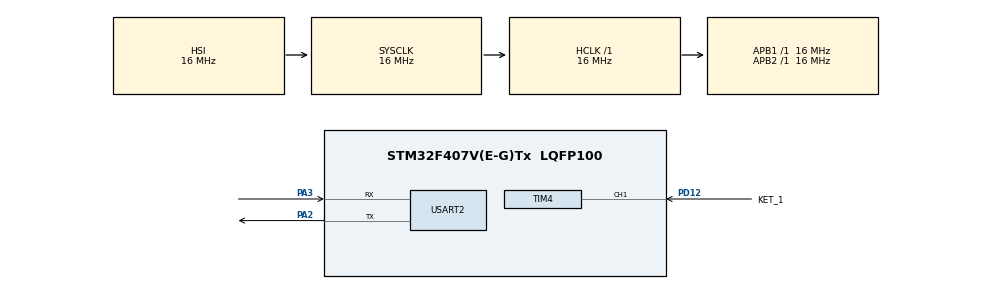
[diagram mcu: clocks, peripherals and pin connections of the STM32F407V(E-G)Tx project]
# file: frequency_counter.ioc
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Mcu.Family=STM32F4
Mcu.Name=STM32F407V(E-G)Tx
Mcu.Package=LQFP100
NVIC.FPU_IRQn=true\:2\:0\:true\:false\:true\:true\:false\:true
NVIC.PriorityGroup=NVIC_PRIORITYGROUP_4
NVIC.TIM4_IRQn=true\:3\:0\:true\:false\:true\:true\:true\:true
NVIC.USART2_IRQn=true\:2\:0\:true\:false\:true\:true\:true\:true
PA2.Mode=Asynchronous
PA2.Signal=USART2_TX
PA3.Mode=Asynchronous
PA3.Signal=USART2_RX
PD12.GPIO_Label=KET_1
PD12.GPIO_PuPd=GPIO_PULLUP
PD12.Signal=S_TIM4_CH1
ProjectManager.HeapSize=0x200
ProjectManager.StackSize=0x400
ProjectManager.TargetToolchain=STM32CubeIDE
RCC.AHBFreq_Value=16000000
RCC.APB1Freq_Value=16000000
RCC.APB2Freq_Value=16000000
RCC.CortexFreq_Value=16000000
RCC.HSE_VALUE=25000000
RCC.HSI_VALUE=16000000
RCC.LSE_VALUE=32768
RCC.SYSCLKFreq_VALUE=16000000
RCC.VCOOutputFreq_Value=192000000
SH.S_TIM4_CH1.0=TIM4_CH1,Input_Capture1_from_TI1
TIM4.Channel-Input_Capture1_from_TI1=TIM_CHANNEL_1
TIM4.Prescaler=72-1
USART2.VirtualMode=VM_ASYNC
VP_TIM4_VS_ClockSourceINT.Mode=Internal
board=custom

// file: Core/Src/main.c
/* USER CODE BEGIN Header */
/**
  ******************************************************************************
  * @file           : main.c
  * @brief          : Main program body
  ******************************************************************************
  * @attention
  *
  * Copyright (c) 2024 STMicroelectronics.
  * All rights reserved.
  *
  * This software is licensed under terms that can be found in the LICENSE file
  * in the root directory of this software component.
  * If no LICENSE file comes with this software, it is provided AS-IS.
  *
  ******************************************************************************
  */
/* USER CODE END Header */
#include "main.h"
#include "tim.h"
#include "usart.h"
#include "gpio.h"

/* USER CODE BEGIN Includes */
#include "stdio.h"
/* USER CODE END Includes */

void SystemClock_Config(void);
/* USER CODE BEGIN PFP */
uint8_t rising_flag = 0;
uint8_t falling_flag = 0;
uint8_t overflow_val = 0;
uint16_t cnt_val = 0;
/* USER CODE END PFP */

/* USER CODE BEGIN 0 */
void HAL_TIM_IC_CaptureCallback(TIM_HandleTypeDef *htim)
{

	if(htim->Instance == TIM4)
	{
		if(falling_flag == 0)
		{
			/*这是捕获到下升沿的操�??*/
			if(rising_flag == 1)
			{
				falling_flag = 1;
				cnt_val = HAL_TIM_ReadCapturedValue(htim, TIM_CHANNEL_1);
				__HAL_TIM_SET_CAPTUREPOLARITY(htim,TIM_CHANNEL_1,TIM_INPUTCHANNELPOLARITY_RISING);
			}
			else
			{
				rising_flag = 0;
				falling_flag = 0;
				overflow_val = 0;
				cnt_val = 0;
				/*这是捕获到上升沿的操�??*/
				rising_flag = 1;
				__HAL_TIM_DISABLE(htim);//close tim
				__HAL_TIM_SET_COUNTER(htim,0);
				__HAL_TIM_SET_CAPTUREPOLARITY(htim,TIM_CHANNEL_1,TIM_INPUTCHANNELPOLARITY_FALLING);
				__HAL_TIM_ENABLE(htim);
			}

		}
	}
}

void HAL_TIM_PeriodElapsedCallback(TIM_HandleTypeDef *htim)
{
	if(htim->Instance == TIM4)
	{
		if(falling_flag == 0)
		{
			if(rising_flag == 1)
			{
				if((overflow_val & 0xFF) ==0xFF) // 判断是否溢出
				{
					//时间太长，强制捕获成�??
					falling_flag = 1;
					__HAL_TIM_SET_CAPTUREPOLARITY(htim,TIM_CHANNEL_1,TIM_INPUTCHANNELPOLARITY_RISING);
					cnt_val = 0xFFFF;
				}
				else
				{
					overflow_val++;
				}
			}
		}
	}
}

void HAL_UART_RxCpltCallback(UART_HandleTypeDef *huart)
{
	if(huart->Instance == USART2)
	HAL_UART_Transmit_IT(&huart2,sendbuf, sizeof(sendbuf));
}
/* USER CODE END 0 */

int main(void)
{

  /* USER CODE BEGIN 1 */
	uint32_t temp = 0;
	uint8_t sendbuf[100] = {};
  /* USER CODE END 1 */

  /* MCU Configuration--------------------------------------------------------*/

  /* Reset of all peripherals, Initializes the Flash interface and the Systick. */
  HAL_Init();

  /* Configure the system clock */
  SystemClock_Config();

  /* Initialize all configured peripherals */
  MX_GPIO_Init();
  MX_TIM4_Init();
  MX_USART2_UART_Init();
  /* USER CODE BEGIN 2 */
  HAL_TIM_Base_Start_IT(&htim4);
  HAL_TIM_IC_Start_IT(&htim4,TIM_CHANNEL_1);
  /* USER CODE END 2 */

  /* Infinite loop */
  /* USER CODE BEGIN WHILE */
  while (1)
  {
	  if(falling_flag == 1)
	  {
		  //按照公式计算
		  temp = overflow_val*65536;
		  temp += cnt_val;
		  falling_flag = 0;
		  rising_flag = 0;
/*这一部分是轮询的串口输出
		  if(temp!=5959870)
		  	  {
			  	  printf("高电平的脉宽长度%ld us\r\n",temp);
		  	  }
*/
	  }

    /* USER CODE END WHILE */

  }
}

void SystemClock_Config(void)
{
  RCC_OscInitTypeDef RCC_OscInitStruct = {0};
  RCC_ClkInitTypeDef RCC_ClkInitStruct = {0};

  /** Configure the main internal regulator output voltage
  */
  __HAL_RCC_PWR_CLK_ENABLE();
  __HAL_PWR_VOLTAGESCALING_CONFIG(PWR_REGULATOR_VOLTAGE_SCALE1);

  /** Initializes the RCC Oscillators according to the specified parameters
  * in the RCC_OscInitTypeDef structure.
  */
  RCC_OscInitStruct.OscillatorType = RCC_OSCILLATORTYPE_HSI;
  RCC_OscInitStruct.HSIState = RCC_HSI_ON;
  RCC_OscInitStruct.HSICalibrationValue = RCC_HSICALIBRATION_DEFAULT;
  RCC_OscInitStruct.PLL.PLLState = RCC_PLL_NONE;
  if (HAL_RCC_OscConfig(&RCC_OscInitStruct) != HAL_OK)
  {
    Error_Handler();
  }

  /** Initializes the CPU, AHB and APB buses clocks
  */
  RCC_ClkInitStruct.ClockType = RCC_CLOCKTYPE_HCLK|RCC_CLOCKTYPE_SYSCLK
                              |RCC_CLOCKTYPE_PCLK1|RCC_CLOCKTYPE_PCLK2;
  RCC_ClkInitStruct.SYSCLKSource = RCC_SYSCLKSOURCE_HSI;
  RCC_ClkInitStruct.AHBCLKDivider = RCC_SYSCLK_DIV1;
  RCC_ClkInitStruct.APB1CLKDivider = RCC_HCLK_DIV1;
  RCC_ClkInitStruct.APB2CLKDivider = RCC_HCLK_DIV1;

  if (HAL_RCC_ClockConfig(&RCC_ClkInitStruct, FLASH_LATENCY_0) != HAL_OK)
  {
    Error_Handler();
  }
}

void Error_Handler(void)
{
  __disable_irq();
  while (1)
  {
  }
}
